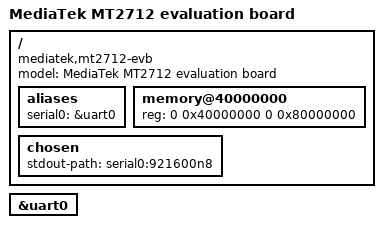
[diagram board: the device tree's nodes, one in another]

/dts-v1/;
#include "mediatek/mt2712e.dtsi"

/ {
	model = "MediaTek MT2712 evaluation board";
	compatible = "mediatek,mt2712-evb", "mediatek,mt2712";

	aliases {
		serial0 = &uart0;
	};

	memory@40000000 {
		device_type = "memory";
		reg = <0 0x40000000 0 0x80000000>;
	};

	chosen {
		stdout-path = "serial0:921600n8";
	};
};

&uart0 {
	status = "okay";
};

